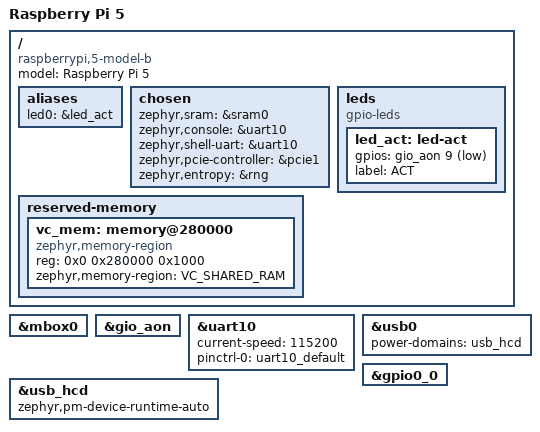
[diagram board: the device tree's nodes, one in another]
/*
 * Copyright 2024 Junho Lee <junho@tsnlab.com>
 *
 * SPDX-License-Identifier: Apache-2.0
 */

/dts-v1/;

#include <broadcom/bcm2712.dtsi>
#include <broadcom/rp1_common.dtsi>
#include <zephyr/dt-bindings/gpio/gpio.h>
#include "rpi_5-pinctrl.dtsi"

/ {
	compatible = "raspberrypi,5-model-b", "brcm,bcm2712";
	model = "Raspberry Pi 5";
	#address-cells = <2>;
	#size-cells = <1>;

	aliases {
		led0 = &led_act;
	};

	chosen {
		zephyr,sram = &sram0;
		zephyr,console = &uart10;
		zephyr,shell-uart = &uart10;
		zephyr,pcie-controller = &pcie1;
		zephyr,entropy = &rng;
	};

	leds {
		compatible = "gpio-leds";

		led_act: led-act {
			gpios = <&gio_aon 9 GPIO_ACTIVE_LOW>;
			label = "ACT";
		};
	};

	reserved-memory {
		ranges;
		#address-cells = <2>;
		#size-cells = <1>;

		/* Keep firmware transactions outside the kernel RAM region. */
		vc_mem: memory@280000 {
			compatible = "zephyr,memory-region";
			reg = <0x0 0x280000 0x1000>;
			zephyr,memory-region = "VC_SHARED_RAM";
		};
	};
};

&mbox0 {
	status = "okay";
};

&gio_aon {
	status = "okay";
};

&uart10 {
	current-speed = <115200>;
	pinctrl-0 = <&uart10_default>;
	pinctrl-names = "default";
	status = "okay";
};

zephyr_udc0: &usb0 {
	power-domains = <&usb_hcd>;
	status = "okay";
};

&usb_hcd {
	zephyr,pm-device-runtime-auto;
};

&gpio0_0 {
	status = "okay";
};
